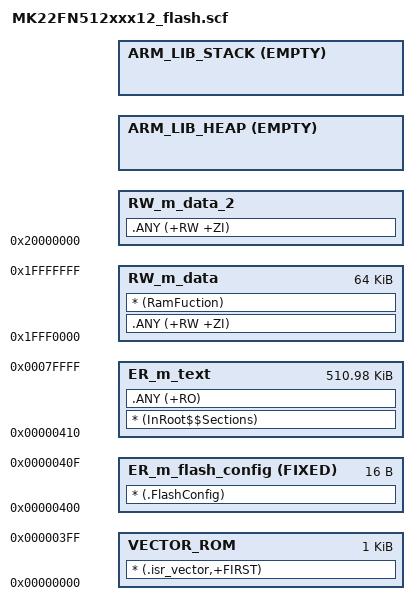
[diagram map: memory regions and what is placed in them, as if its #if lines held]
#!armclang --target=arm-arm-none-eabi -mcpu=cortex-m4 -E -x c
/*
** ###################################################################
**     Processors:          MK22FN512CAP12
**                          MK22FN512VDC12
**                          MK22FN512VFX12
**                          MK22FN512VLH12
**                          MK22FN512VLL12
**                          MK22FN512VMP12
**
**     Compiler:            Keil ARM C/C++ Compiler
**     Reference manual:    K22P121M120SF7RM, Rev. 1, March 24, 2014
**     Version:             rev. 2.9, 2016-03-21
**     Build:               b190916
**
**     Abstract:
**         Linker file for the Keil ARM C/C++ Compiler
**
**     Copyright 2016 Freescale Semiconductor, Inc.
**     Copyright 2016-2019 NXP
**     All rights reserved.
**
**     SPDX-License-Identifier: BSD-3-Clause
**
**     http:                 www.nxp.com
**     mail:                 support@nxp.com
**
** ###################################################################
*/

#define m_interrupts_start             0x00000000
#define m_interrupts_size              0x00000400

#define m_flash_config_start           0x00000400
#define m_flash_config_size            0x00000010

#define m_text_start                   0x00000410
#define m_text_size                    0x0007FBF0

#define m_data_start                   0x1FFF0000
#define m_data_size                    0x00010000

#define m_data_2_start                 0x20000000
#define m_data_2_size                  0x00010000

/* Sizes */
#if (defined(__stack_size__))
  #define Stack_Size                   __stack_size__
#else
  #define Stack_Size                   0x2000
#endif

#if (defined(__heap_size__))
  #define Heap_Size                    __heap_size__
#else
  #define Heap_Size                    0x2000
#endif

LR_m_text m_interrupts_start m_text_start+m_text_size-m_interrupts_start { ; load region size_region
  VECTOR_ROM m_interrupts_start m_interrupts_size { ; load address = execution address
    * (.isr_vector,+FIRST)
  }
  ER_m_flash_config m_flash_config_start FIXED m_flash_config_size { ; load address = execution address
    * (.FlashConfig)
  }
  ER_m_text m_text_start m_text_size { ; load address = execution address
    * (InRoot$$Sections)
    .ANY (+RO)
  }

  RW_m_data m_data_start m_data_size { ; RW data
    .ANY (+RW +ZI)
    * (RamFuction)
  }
  RW_m_data_2 m_data_2_start m_data_2_size-Stack_Size-Heap_Size { ; RW data
    .ANY (+RW +ZI)
  }
  ARM_LIB_HEAP ((ImageLimit(RW_m_data_2) == m_data_2_start) ? m_data_2_start : +0) EMPTY Heap_Size { ; Heap region growing up
  }
  ARM_LIB_STACK m_data_2_start+m_data_2_size EMPTY -Stack_Size { ; Stack region growing down
  }
}

